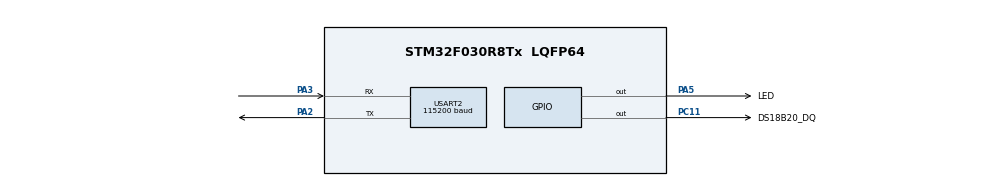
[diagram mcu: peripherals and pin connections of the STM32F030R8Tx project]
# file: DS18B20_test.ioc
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Mcu.Family=STM32F0
Mcu.Name=STM32F030R8Tx
Mcu.Package=LQFP64
NVIC.USART2_IRQn=true\:0\:0\:false\:false\:true\:true
PA2.Mode=Asynchronous
PA2.Signal=USART2_TX
PA3.Mode=Asynchronous
PA3.Signal=USART2_RX
PA5.GPIO_Label=LED
PA5.Signal=GPIO_Output
PC11.GPIO_Label=DS18B20_DQ
PC11.Signal=GPIO_Output
ProjectManager.HeapSize=0x200
ProjectManager.StackSize=0x400
ProjectManager.TargetToolchain=MDK-ARM V5
USART2.BaudRate=115200
USART2.VirtualMode-Asynchronous=VM_ASYNC
board=DS18B20_test

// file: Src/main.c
/**
  ******************************************************************************
  * File Name          : main.c
  * Description        : Main program body
  ******************************************************************************
  ** This notice applies to any and all portions of this file
  * that are not between comment pairs USER CODE BEGIN and
  * USER CODE END. Other portions of this file, whether
  * inserted by the user or by software development tools
  * are owned by their respective copyright owners.
  *
  * COPYRIGHT(c) 2017 STMicroelectronics
  *
  * Redistribution and use in source and binary forms, with or without modification,
  * are permitted provided that the following conditions are met:
  *   1. Redistributions of source code must retain the above copyright notice,
  *      this list of conditions and the following disclaimer.
  *   2. Redistributions in binary form must reproduce the above copyright notice,
  *      this list of conditions and the following disclaimer in the documentation
  *      and/or other materials provided with the distribution.
  *   3. Neither the name of STMicroelectronics nor the names of its contributors
  *      may be used to endorse or promote products derived from this software
  *      without specific prior written permission.
  *
  * THIS SOFTWARE IS PROVIDED BY THE COPYRIGHT HOLDERS AND CONTRIBUTORS "AS IS"
  * AND ANY EXPRESS OR IMPLIED WARRANTIES, INCLUDING, BUT NOT LIMITED TO, THE
  * IMPLIED WARRANTIES OF MERCHANTABILITY AND FITNESS FOR A PARTICULAR PURPOSE ARE
  * DISCLAIMED. IN NO EVENT SHALL THE COPYRIGHT HOLDER OR CONTRIBUTORS BE LIABLE
  * FOR ANY DIRECT, INDIRECT, INCIDENTAL, SPECIAL, EXEMPLARY, OR CONSEQUENTIAL
  * DAMAGES (INCLUDING, BUT NOT LIMITED TO, PROCUREMENT OF SUBSTITUTE GOODS OR
  * SERVICES; LOSS OF USE, DATA, OR PROFITS; OR BUSINESS INTERRUPTION) HOWEVER
  * CAUSED AND ON ANY THEORY OF LIABILITY, WHETHER IN CONTRACT, STRICT LIABILITY,
  * OR TORT (INCLUDING NEGLIGENCE OR OTHERWISE) ARISING IN ANY WAY OUT OF THE USE
  * OF THIS SOFTWARE, EVEN IF ADVISED OF THE POSSIBILITY OF SUCH DAMAGE.
  *
  ******************************************************************************
  */
#include "main.h"
#include "stm32f0xx_hal.h"
#include "hwcfg.h"
#include "18B20.h"

/* USER CODE BEGIN PV */
/* Private variables ---------------------------------------------------------*/

/* USER CODE END PV */

/* USER CODE BEGIN PFP */
/* Private function prototypes -----------------------------------------------*/

/* USER CODE END PFP */

void delay_us(uint16_t time);
void delay_ms(uint16_t time);

int main(void)
{

  /* MCU Configuration----------------------------------------------------------*/

  /* Reset of all peripherals, Initializes the Flash interface and the Systick. */
  HAL_Init();

  /* Configure the system clock */
  SystemClock_Config();

  /* Initialize all configured peripherals */
  MX_GPIO_Init();
  MX_USART2_UART_Init();
  LED_ON();
  /* USER CODE BEGIN 2 */
  printf("start");
  /* USER CODE END 2 */
  /* Infinite loop */
  while (1)
  {
    LED_ON();
		delay_ms(500);
    LED_OFF();
		delay_ms(500);
  /* USER CODE BEGIN 3 */
    if(Init18b20())
			{
					printf("\n\rNO Find DS18B20 !\n\r");
			}
			else
			{
					printf("\n\rCurrent Temperature = %0.4lf ��\n\r",TemperatuerResult());
			}
  }
  /* USER CODE END 3 */

}
void delay_us(uint16_t time)
{
   uint16_t i=0;
   while(time--)
   {
      i=1;  //�Լ�����
      while(i--) ;
   }
}
void delay_ms(uint16_t time)
{
   uint16_t i=0;
   while(time--)
   {
      i=1370;  //�Լ�����
      while(i--) ;
   }
}

void _Error_Handler(char * file, int line)
{
  while(1)
  {
  }
}

/************************ (C) COPYRIGHT STMicroelectronics *****END OF FILE****/
